# CY8C5868AXI_LP035 register map
File version: 0.1
CY8C58LP
Registers are 8-bit, read-write, no defined reset value unless marked. A register's access mark holds for its fields unless they carry their own. Offsets are from the block's base; lines under a group give offsets from that group; [hi:lo] are bit positions; {n}, {i} and the like mark numbered series; 'fields as' and 'values as' point back to an identical list; <NAME> marks a mode.

## Memory map
0x00000000 MIDI1_UART — UART
0x00000000 SleepTimer
0x00000000 USB — USBFS
0x00000000 MIDI2_UART — UART

## MIDI1_UART — UART
Base 0x00000000
0x4000644A TX_MIDI1_UART_TX_DATA — TX Data Register
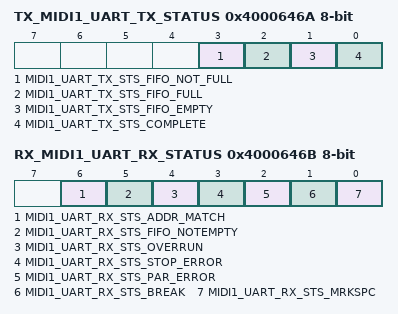
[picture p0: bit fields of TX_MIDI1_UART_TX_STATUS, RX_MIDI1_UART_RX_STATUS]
0x4000646A TX_MIDI1_UART_TX_STATUS — TX status register
  [3] MIDI1_UART_TX_STS_FIFO_NOT_FULL ro, [2] MIDI1_UART_TX_STS_FIFO_FULL ro, [1] MIDI1_UART_TX_STS_FIFO_EMPTY ro, [0] MIDI1_UART_TX_STS_COMPLETE ro
0x4000646B RX_MIDI1_UART_RX_STATUS — RX status register
  [6] MIDI1_UART_RX_STS_ADDR_MATCH ro, [5] MIDI1_UART_RX_STS_FIFO_NOTEMPTY ro, [4] MIDI1_UART_RX_STS_OVERRUN ro, [3] MIDI1_UART_RX_STS_STOP_ERROR ro, [2] MIDI1_UART_RX_STS_PAR_ERROR ro, [1] MIDI1_UART_RX_STS_BREAK ro, [0] MIDI1_UART_RX_STS_MRKSPC ro
0x40006528 RX_MIDI1_UART_RX_ADDRESS1 — RX Address1 Register
0x40006538 RX_MIDI1_UART_RX_ADDRESS2 — RX Address2 Register
0x40006548 RX_MIDI1_UART_RX_DATA — RX Data Register

## SleepTimer
Base 0x00000000
0x40004381 SleepTimer_CTW_INTERVAL_REG — Timewheel Configuration Register 1
  [3:0] ctw_interval — Sets the central timewheel interval.
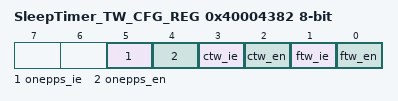
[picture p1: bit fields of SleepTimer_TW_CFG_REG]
0x40004382 SleepTimer_TW_CFG_REG — Timewheel Configuration Register 2
  [5] onepps_ie — When set and one pulse-per-second is enabled, an interrupt is issued when the pulse occurs.
    1=Enabled (One PPS interrupt is enabled); 0=Disabled (One PPS interrupt is disabled)
  [4] onepps_en — When set, the system returns to the active global power mode once every second.
    1=Enabled (One PPS is enabled); 0=Disabled (One PPS is disabled)
  [3] ctw_ie — When set and the central timewheel is enabled, an interrupt is issued when the central timewheel reaches the selected interval.
    1=Enabled (CTW interrupt is enabled); 0=Disabled (CTW interrupt is disabled)
  [2] ctw_en — When set, the system returns to the active global power mode when the central timewheel reaches the selected interval.
    1=Enabled (CTW is enabled); 0=Disabled (CTW is disabled)
  [1] ftw_ie — When set and the fast timewheel is enabled, an interrupt is issued when it reaches the terminal count.
    1=Enabled (FTW interrupt is enabled); 0=Disabled (FTW interrupt is disabled)
  [0] ftw_en — When set, the system returns to the active global power mode when the fast timewheel reaches the selected interval.
    1=Enabled (FTW is enabled); 0=Disabled (FTW is disabled)

## USB — USBFS
Base 0x00000000
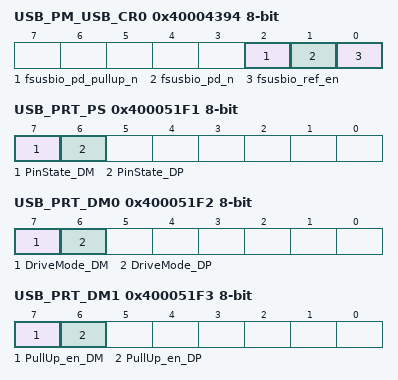
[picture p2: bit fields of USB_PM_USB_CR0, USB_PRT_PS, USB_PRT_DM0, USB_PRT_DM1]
0x40004394 USB_PM_USB_CR0 — USB Power Mode Control Register 0
  [2] fsusbio_pd_pullup_n, [1] fsusbio_pd_n, [0] fsusbio_ref_en
0x400043A5 USB_PM_ACT_CFG — Active Power Mode Configuration Register
0x400043B5 USB_PM_STBY_CFG — Standby Power Mode Configuration Register
0x400051F1 USB_PRT_PS — Port Pin State Register
  [7] PinState_DM ro, [6] PinState_DP ro
0x400051F2 USB_PRT_DM0 — Port Drive Mode Register
  [7] DriveMode_DM, [6] DriveMode_DP
0x400051F3 USB_PRT_DM1 — Port Drive Mode Register
  [7] PullUp_en_DM, [6] PullUp_en_DP
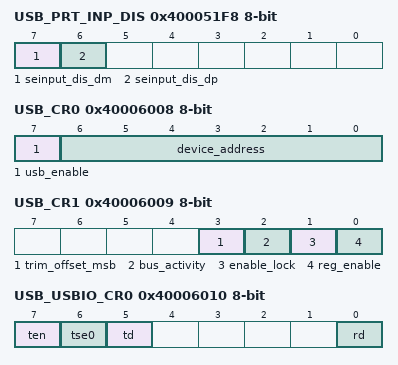
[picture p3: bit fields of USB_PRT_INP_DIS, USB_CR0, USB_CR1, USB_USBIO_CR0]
0x400051F8 USB_PRT_INP_DIS — Input buffer disable override
  [7] seinput_dis_dm, [6] seinput_dis_dp
0x40006000 USB_EP0_DR0 — bmRequestType
0x40006001 USB_EP0_DR1 — bRequest
0x40006002 USB_EP0_DR2 — wValueLo
0x40006003 USB_EP0_DR3 — wValueHi
0x40006004 USB_EP0_DR4 — wIndexLo
0x40006005 USB_EP0_DR5 — wIndexHi
0x40006006 USB_EP0_DR6 — lengthLo
0x40006007 USB_EP0_DR7 — lengthHi
0x40006008 USB_CR0 — USB Control Register 0
  [7] usb_enable, [6:0] device_address ro
0x40006009 USB_CR1 — USB Control Register 1
  [3] trim_offset_msb, [2] bus_activity, [1] enable_lock, [0] reg_enable
{0x40005FFE+0x10*i} USB_SIE_EP{i}_CR0 (i=1..8) — The Endpoint{i} Control Register
0x40006010 USB_USBIO_CR0 — USBIO Control Register 0
  [7] ten, [6] tse0, [5] td, [0] rd ro
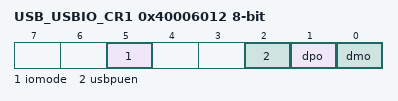
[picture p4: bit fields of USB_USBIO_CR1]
0x40006012 USB_USBIO_CR1 — USBIO Control Register 1
  [5] iomode, [2] usbpuen, [1] dpo ro, [0] dmo ro
0x4000608C USB_BUF_SIZE — Dedicated Endpoint Buffer Size Register
0x4000608E USB_EP_ACTIVE — Endpoint Active Indication Register
0x4000608F USB_EP_TYPE — Endpoint Type (IN/OUT) Indication
0x4000609D USB_USB_CLK_EN — USB Block Clock Enable Register

## MIDI2_UART — UART
Base 0x00000000
0x40006449 TX_MIDI2_UART_TX_DATA — TX Data Register
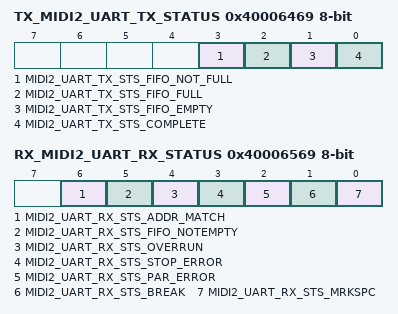
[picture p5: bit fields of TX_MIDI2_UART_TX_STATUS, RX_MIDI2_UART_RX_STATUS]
0x40006469 TX_MIDI2_UART_TX_STATUS — TX status register
  [3] MIDI2_UART_TX_STS_FIFO_NOT_FULL ro, [2] MIDI2_UART_TX_STS_FIFO_FULL ro, [1] MIDI2_UART_TX_STS_FIFO_EMPTY ro, [0] MIDI2_UART_TX_STS_COMPLETE ro
0x4000652A RX_MIDI2_UART_RX_ADDRESS1 — RX Address1 Register
0x4000653A RX_MIDI2_UART_RX_ADDRESS2 — RX Address2 Register
0x4000654A RX_MIDI2_UART_RX_DATA — RX Data Register
0x40006569 RX_MIDI2_UART_RX_STATUS — RX status register
  [6] MIDI2_UART_RX_STS_ADDR_MATCH ro, [5] MIDI2_UART_RX_STS_FIFO_NOTEMPTY ro, [4] MIDI2_UART_RX_STS_OVERRUN ro, [3] MIDI2_UART_RX_STS_STOP_ERROR ro, [2] MIDI2_UART_RX_STS_PAR_ERROR ro, [1] MIDI2_UART_RX_STS_BREAK ro, [0] MIDI2_UART_RX_STS_MRKSPC ro
